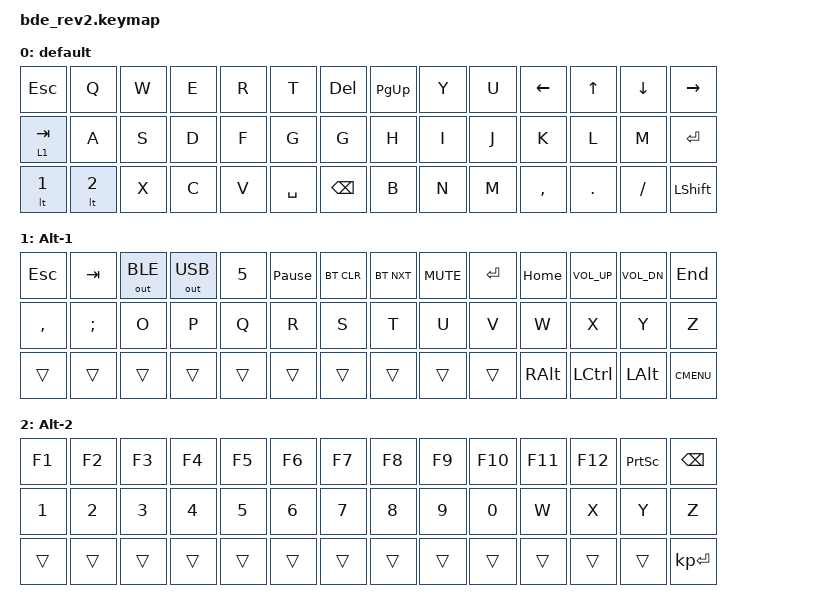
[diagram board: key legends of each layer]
/*
 * Copyright (c) 2022 The ZMK Contributors
 *
 * SPDX-License-Identifier: MIT
 */

#include <behaviors.dtsi>
#include <dt-bindings/zmk/bt.h>
#include <dt-bindings/zmk/keys.h>
#include <dt-bindings/zmk/outputs.h>

&kscan {
    row-gpios
            = <&pro_micro  5 (GPIO_ACTIVE_HIGH | GPIO_PULL_DOWN)>
            , <&pro_micro  6 (GPIO_ACTIVE_HIGH | GPIO_PULL_DOWN)>
            , <&pro_micro  0 (GPIO_ACTIVE_HIGH | GPIO_PULL_DOWN)>
            , <&pro_micro  4 (GPIO_ACTIVE_HIGH | GPIO_PULL_DOWN)>
            , <&pro_micro  7 (GPIO_ACTIVE_HIGH | GPIO_PULL_DOWN)>
            , <&pro_micro 16 (GPIO_ACTIVE_HIGH | GPIO_PULL_DOWN)>
            ;
};

/ {

    keymap {
        compatible = "zmk,keymap";

        default_layer {
            display-name = "default";
            bindings = <
    &kp ESC      &kp Q       &kp W        &kp E           &kp R          &kp T           &kp DEL     &kp PG_UP   &kp Y       &kp U        &kp LEFT   &kp UP       &kp DOWN     &kp RIGHT
    &lt 1 TAB    &kp A       &kp S        &kp D           &kp F          &kp G           &kp G       &kp H       &kp I       &kp J        &kp K      &kp L        &kp M        &kp ENTER
    &lt 1        &lt 2       &kp X        &kp C           &kp V          &kp SPACE       &kp BSPC    &kp B       &kp N       &kp M        &kp COMMA  &kp DOT      &kp FSLH     &kp LSHFT
            >;
        };
        alt1_layer {
            display-name = "Alt-1";
            bindings = <
    &kp ESC      &kp TAB     &out OUT_BLE &out OUT_USB    &kp N5         &kp PAUSE_BREAK &bt BT_CLR  &bt BT_NXT  &kp K_MUTE  &kp ENTER    &kp HOME   &kp K_VOL_UP &kp K_VOL_DN &kp END
    &kp COMMA    &kp SEMI    &kp O        &kp P           &kp Q          &kp R           &kp S       &kp T       &kp U       &kp V        &kp W      &kp X        &kp Y        &kp Z
    &trans       &trans      &trans       &trans          &trans         &trans          &trans      &trans      &trans      &trans       & RALT     & LCTRL       & LALT      &kp K_CMENU
            >;
        };
        alt2_layer {
            display-name = "Alt-2";
            bindings = <
    &kp F1       &kp F2      &kp F3       &kp F4          &kp F5         &kp F6          &kp F7      &kp F8      &kp F9      &kp F10      &kp F11    &kp F12      &kp PSCRN    &kp BACKSPACE
    &kp N1       &kp N2      &kp N3       &kp N4          &kp N5         &kp N6          &kp N7      &kp N8      &kp N9      &kp N0       &kp W      &kp X        &kp Y        &kp Z
    &trans      &trans       &trans       &trans          &trans         &trans          &trans      &trans      &trans      &trans       &trans     &trans       &trans       &kp KP_ENTER
            >;  
        };
        
    };
};
